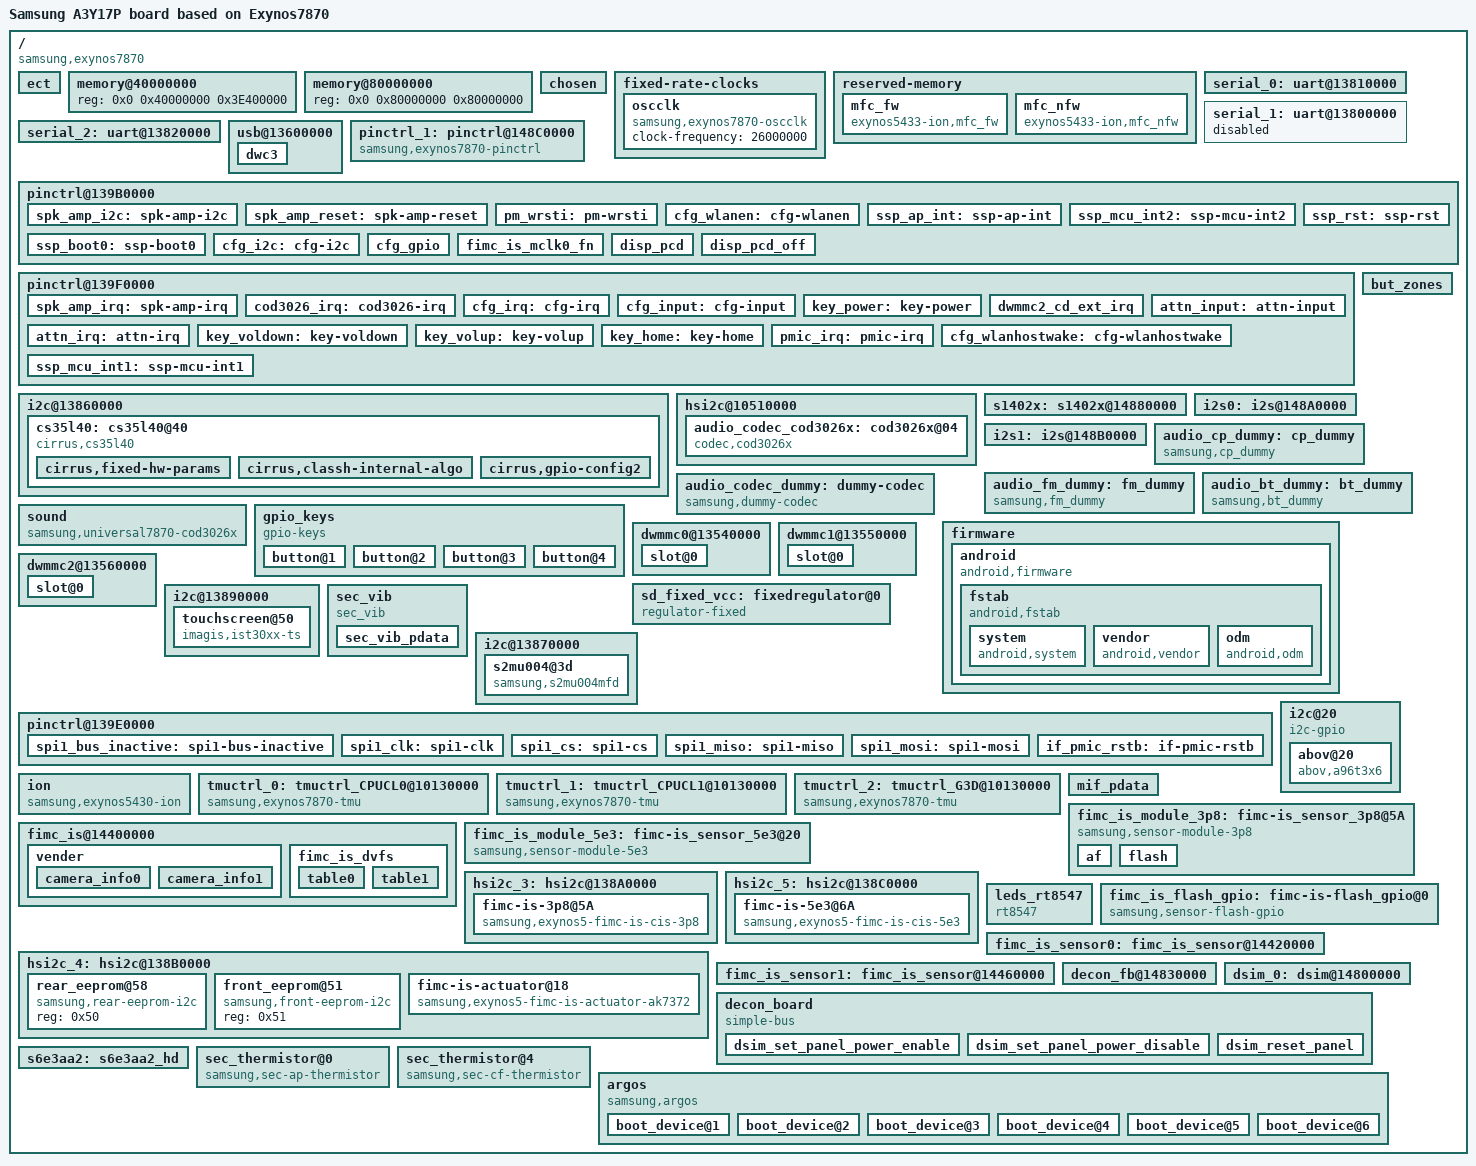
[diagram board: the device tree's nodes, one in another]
/*
 * Copyright (c) 2016 Samsung Electronics Co., Ltd.
 *		http://www.samsung.com
 *
 * This program is free software; you can redistribute it and/or modify
 * it under the terms of the GNU General Public License version 2 as
 * published by the Free Software Foundation.
*/

#include "exynos7870-rmem-3000MB.dtsi"
#include "exynos7870.dtsi"

/ {
	model = "Samsung A3Y17P board based on Exynos7870";
	compatible = "samsung,exynos7870", "samsung,universal7870";

	ect {
		parameter_address = <0x90000000>;
		parameter_size = <0x14000>;	/* u-boot always overwrites this value. */
	};

	memory@40000000 {
		device_type = "memory";
		reg = <0x0 0x40000000 0x3E400000>;
	};

	memory@80000000 {
		device_type = "memory";
		reg = <0x0 0x80000000 0x80000000>;
	};

	chosen {
		bootargs = "console=ram ess_setup=0x46000000 androidboot.hardware=samsungexynos7870 androidboot.selinux=disabled firmware_class.path=/vendor/firmware androidboot.debug_level=0x4948 reserve-fimc=0";
		linux,initrd-start = <0x42000000>;
		linux,initrd-end = <0x420FFFFF>;
	};

	fixed-rate-clocks {
		oscclk {
			compatible = "samsung,exynos7870-oscclk";
			clock-frequency = <26000000>;
		};
	};

	reserved-memory {
		#address-cells = <2>;
		#size-cells = <1>;
		ranges;

		mfc_fw {
			compatible = "exynos5433-ion,mfc_fw";
			secure;
			reg = <0x0 0xAE800000 0x200000>;
			id = <8>;
		};

		mfc_nfw {
			compatible = "exynos5433-ion,mfc_nfw";
			reg = <0x0 0xAE600000 0x200000>;
			id = <12>;
		};
	};

	serial_0: uart@13810000 {
		status = "okay";
	};

	serial_1: uart@13800000 {
		status = "disabled";
	};

	serial_2: uart@13820000 {
		status = "okay";
	};

	usb@13600000 {
		status = "okay";

		dwc3 {
			maximum-speed = "high-speed";
			dr_mode = "otg";
			is_not_vbus_pad;
		};
	};

	pinctrl_1: pinctrl@148C0000 {
		compatible = "samsung,exynos7870-pinctrl";
		reg = <0x0 0x148C0000 0x1000>;
		interrupts = <0 68 0>;
	};

	pinctrl@139B0000 {
		spk_amp_i2c: spk-amp-i2c {
			samsung,pins = "gpc9-1", "gpc9-0";
			samsung,pin-function = <2>;
			samsung,pin-pud = <0>;
		};

		spk_amp_reset: spk-amp-reset {
			samsung,pins = "gpd1-5";
			samsung,pin-function = <1>;
			samsung,pin-pud = <0>;
			samsung,pin-val = <0>;
			samsung,pin-con-pdn = <3>;
			samsung,pin-pud-pdn = <0>;
		};
	};

	pinctrl@139F0000 {
		spk_amp_irq: spk-amp-irq {
			samsung,pins = "gpa2-5";
			samsung,pin-function = <0xf>;
			samsung,pin-pud = <0>;
		};

		cod3026_irq: cod3026-irq {
			samsung,pins = "gpa0-4";
			samsung,pin-pud = <3>;
			samsung,pin-drv = <3>;
		};
	};

	i2c@13860000 {
		status = "okay";
		samsung,i2c-max-bus-freq = <400000>;
		pinctrl-names = "default";
		pinctrl-0 = <&spk_amp_i2c &spk_amp_reset &spk_amp_irq>;

		cs35l40: cs35l40@40 {
			#sound-dai-cells = <1>;
			compatible = "cirrus,cs35l40";
			reg = <0x40>;

			interrupt-parent = <&gpa2>;
			interrupts = <5 0 0>;

			cirrus,boost-peak-milliamp = <3100>;
			cirrus,temp-warn-threshold = <2>;

			cirrus,dsp-noise-gate-enable;
			cirrus,dsp-noise-gate-threshold = <0x3>;
			cirrus,dsp-noise-gate-delay = <0x7>;

			cirrus,hw-noise-gate-select = <0x3F>;
			cirrus,hw-noise-gate-delay = <0x7>;
			cirrus,hw-noise-gate-threshold = <0x7>;

			reset-gpios = <&gpd1 5 0>;

			cirrus,fixed-hw-params {
				cirrus,fixed-rate = <48000>;
				cirrus,fixed-width = <16>;
				cirrus,fixed-wl = <16>;
			};

			cirrus,classh-internal-algo {
				cirrus,classh-headroom = <0xb>;
				cirrus,classh-release-rate = <0x4>;
				cirrus,classh-mem-depth = <0x5>;
				cirrus,classh-wk-fet-delay = <0x4>;
				cirrus,classh-wk-fet-thld = <0x1>;
			};

			cirrus,gpio-config2 {
				cirrus,gpio-src-select = <0x4>;
				cirrus,gpio-output-enable;
			};
		};
	};

	but_zones: but_zones {
		#list-but-cells = <3>;
	};

	hsi2c@10510000 {
		audio_codec_cod3026x: cod3026x@04 {
			compatible = "codec,cod3026x";
			reg = <0x04>;
			ten-bit-address;
			vdd-supply = <&ldo25_reg>;
			pinctrl-names = "default";
			pinctrl-0 = <&cod3026_irq>;
			interrupt-parent = <&gpa0>;
			gpios = <&gpa0 4 0xf &gpd2 1 0x1>;
			ant-det-gpio = <&gpa2 3 0xf>;
			mic-bias1-voltage = <1>;
			mic-bias2-voltage = <1>;
			mic-bias-ldo-voltage = <3>;
			use-det-adc-mode;
			use-det-gdet-adc-mode = <2>;
			io-channels = <&exynos_adc 2>;
			io-channel-names = "adc-jack";
			#io-channel-cells = <1>;
			io-channel-ranges;
			but-zones-list = <&but_zones 226 0 390>, /* send/end */
					<&but_zones 582 391 465>, /* google */
					<&but_zones 115 466 650>, /* vol up */
					<&but_zones 114 651 1100>; /* vol down */
			mic-adc-range = <1430>;
			ant-adc-range = <3560>;
			mic-det-delay = <550>;
		};
	};

	s1402x: s1402x@14880000 {
		pinctrl-names = "default", "idle", "bt", "bt-idle", "fm", "fm-idle";
		pinctrl-0 = <&i2s_pmic_amp_bus
			&i2s_amp_bus>;
		pinctrl-1 = <&i2s_pmic_amp_bus_idle
			&i2s_amp_bus_idle> ;
		pinctrl-2 = <&i2s_bt_bus>;
		pinctrl-3 = <&i2s_bt_bus_idle>;
		pinctrl-4 = <&i2s_bt_bus>;
		pinctrl-5 = <&i2s_bt_bus_idle>;

		bt-fm-combo;
		status = "okay";
	};

	i2s0: i2s@148A0000 {
		status = "okay";
	};

	i2s1: i2s@148B0000 {
		status = "okay";
	};

	audio_cp_dummy: cp_dummy {
			compatible = "samsung,cp_dummy";
			status = "okay";
	};

	audio_fm_dummy: fm_dummy {
			compatible = "samsung,fm_dummy";
			status = "okay";
	};

	audio_bt_dummy: bt_dummy {
			compatible = "samsung,bt_dummy";
			status = "okay";
	};

	audio_codec_dummy: dummy-codec {
			compatible = "samsung,dummy-codec";
			status = "okay";
	};

	sound {
		compatible = "samsung,universal7870-cod3026x";
		samsung,audio-cpu = <&i2s0      /* primary */
			&i2s0                    /* secondary */
			&audio_cp_dummy
			&audio_bt_dummy
			&audio_fm_dummy
			&i2s1			/*AMP for AP */
			&audio_cp_dummy		/*AMP for CP */
			&eax
			&eax
			&eax
			&eax>;
		samsung,audio-codec = <&audio_codec_cod3026x
			&audio_codec_cod3026x
			&audio_codec_cod3026x
			&audio_codec_dummy
			&audio_codec_cod3026x
			&audio_codec_dummy
			&audio_codec_dummy
			&audio_codec_cod3026x
			&audio_codec_cod3026x
			&audio_codec_cod3026x
			&audio_codec_cod3026x>;
		samsung,audio-amp-num = <1>;
		samsung,audio-amp = <&cs35l40
			&cs35l40
			&cs35l40
			&audio_codec_dummy
			&cs35l40
			&cs35l40
			&audio_codec_dummy
			&cs35l40
			&cs35l40
			&cs35l40
			&cs35l40>;
		samsung,audio-amp-dai-name = "cs35l40-pcm",
			"cs35l40-pcm",
			"cs35l40-pcm",
			"dummy-aif2",
			"cs35l40-pcm",
			"cs35l40-pcm",
			"dummy-aif2",
			"cs35l40-pcm",
			"cs35l40-pcm",
			"cs35l40-pcm",
			"cs35l40-pcm";
		mic-bias-mode = <1 1 2 0>;
		samsung,auxdev = <&s1402x>;
		status = "okay";
	};

	gpio_keys {
		compatible = "gpio-keys";
		pinctrl-names = "default";
		pinctrl-0 = <&key_power &key_voldown &key_volup &key_home>;
		#address-cells = <1>;
		#size-cells = <0>;

		button@1 {
			label = "gpio-keys: KEY_POWER";
			interrupts = <0 0 0>;
			interrupt-parent = <&gpa0>;
			linux,code = <116>;
			gpios = <&gpa0 0 0xf>;
			gpio-key,wakeup = <1>;
		};
		button@2 {
			label = "gpio-keys: KEY_VOLUMEDOWN";
			interrupts = <1 0 0>;
			interrupt-parent = <&gpa2>;
			linux,code = <114>;
			gpios = <&gpa2 1 0xf>;
		};
		button@3 {
			label = "gpio-keys: KEY_VOLUMEUP";
			interrupts = <0 0 0>;
			interrupt-parent = <&gpa2>;
			linux,code = <115>;
			gpios = <&gpa2 0 0xf>;
		};
		button@4 {
			label = "gpio-keys: KEY_HOMEPAGE";
			interrupts = <7 0 0>;
			interrupt-parent = <&gpa1>;
			linux,code = <172>;
			gpios = <&gpa1 7 0xf>;
			gpio-key,wakeup = <1>;
		};
	};

	firmware {
		android {
			compatible = "android,firmware";
			fstab {
				compatible = "android,fstab";
				system {
					compatible = "android,system";
					dev = "/dev/block/platform/13540000.dwmmc0/by-name/SYSTEM";
					type = "ext4";
					mnt_flags = "ro";
					fsmgr_flags = "wait";
				};
				vendor {
					compatible = "android,vendor";
					dev = "/dev/block/platform/13540000.dwmmc0/by-name/VENDOR";
					type = "ext4";
					mnt_flags = "ro";
					fsmgr_flags = "wait";
				};
				odm {
					compatible = "android,odm";
					dev = "/dev/block/platform/13540000.dwmmc0/by-name/ODM";
					type = "ext4";
					mnt_flags = "ro";
					fsmgr_flags = "wait";
				};
			};
		};
	};

	dwmmc0@13540000 {
		status = "okay";
		num-slots = <1>;
		broken-cd;
		use-smu;
		fixed_voltage;
		clock-gate;
		supports-highspeed;
		mmc-ddr-1_8v;
		mmc-hs200-1_8v;
		mmc-hs400-1_8v;
		mmc-shutdown-poweroff;
		pm-skip-mmc-resume-init;
		supports-8bit;
		supports-cmd23;
		supports-erase;
		enable-ulp-mode;
		supports-hs400-enhanced-strobe;
		use-fine-tuning;
		bypass-for-allpass;
		card-init-hwacg-ctrl;
		fifo-depth = <0x40>;
		non-removable;
		desc-size = <4>;
		card-detect-delay = <200>;
		data-timeout = <200>;
		clock-frequency = <800000000>;
		samsung,dw-mshc-ciu-div = <3>;
		samsung,dw-mshc-txdt-crc-timer-fastlimit = <0x34>;
		samsung,dw-mshc-txdt-crc-timer-initval = <0x38>;
		samsung,dw-mshc-ddr200-delay-line = <0x60>;
		samsung,dw-mshc-sdr-timing = <3 0 4 0>;
		samsung,dw-mshc-ddr-timing = <3 0 4 2>;
		samsung,dw-mshc-hs200-timing = <3 0 3 0>;
		samsung,dw-mshc-ddr200-timing = <1 0 4 0>;
		samsung,dw-mshc-ddr200-ulp-timing = <3 0 3 0>;

		num-ref-clks = <12>;
		ciu_clkin = <25 50 50 25 50 100 200 50 50 200 200 200>;

		/* Swapping clock drive strength */
		clk-drive-number = <6>;
		pinctrl-names = "default",
			"fast-slew-rate-1x",
			"fast-slew-rate-2x",
			"fast-slew-rate-3x",
			"fast-slew-rate-4x",
			"fast-slew-rate-5x",
			"fast-slew-rate-6x";
		pinctrl-0 = <&sd0_clk &sd0_cmd &sd0_rdqs &sd0_bus1 &sd0_bus4 &sd0_bus8>;
		pinctrl-1 = <&sd0_clk_fast_slew_rate_1x>;
		pinctrl-2 = <&sd0_clk_fast_slew_rate_2x>;
		pinctrl-3 = <&sd0_clk_fast_slew_rate_3x>;
		pinctrl-4 = <&sd0_clk_fast_slew_rate_4x>;
		pinctrl-5 = <&sd0_clk_fast_slew_rate_5x>;
		pinctrl-6 = <&sd0_clk_fast_slew_rate_6x>;
		slot@0 {
			reg = <0>;
			bus-width = <8>;
		};
	};

	dwmmc1@13550000 {
		status = "okay";
		num-slots = <1>;
		channel = <1>;
		fixed_voltage;
		clock-gate;
		enable-cclk-on-suspend;
		caps-control;
		supports-highspeed;
		supports-4bit;
		sd-uhs-sdr104;
		keep-power-in-suspend;
		pm-ignore-notify;
		card-detect-type-external;
		use-broken-voltage;
		use-fine-tuning;
		ignore-phase = <(1 << 7)>;
		fifo-depth = <0x40>;
		card-detect-delay = <200>;
		samsung,dw-mshc-ciu-div = <3>;
		samsung,dw-mshc-sdr-timing = <3 0 3 0>;
		samsung,dw-mshc-ddr-timing = <3 0 2 1>;
		samsung,dw-mshc-sdr50-timing = <3 0 4 2>;
		samsung,dw-mshc-sdr104-timing = <3 0 3 0>;
		clk_pin = "gpr2-0";
		clk_addr = "13750000.pinctrl";
		clk_val = <0x2>;
		clk_str_num = <4>;
		num-ref-clks = <9>;
		ciu_clkin = <25 50 50 25 50 100 200 50 50>;

		pinctrl-names = "default";
		pinctrl-0 = <&sd1_clk &sd1_cmd &sd1_bus1 &sd1_bus4>;
		slot@0 {
			reg = <0>;
			bus-width = <4>;
		};
	};

	dwmmc2@13560000 {
		status = "okay";
		num-slots = <1>;
		supports-highspeed;
		supports-4bit;
		supports-cmd23;
		supports-erase;
		sd-uhs-sdr50;
		sd-uhs-sdr104;
		card-detect-gpio;
		clock-gate;
		bypass-smu;
		bypass-for-allpass;
		use-fine-tuning;
		card-init-hwacg-ctrl;
		only_once_tune;
		//skip-init-mmc-scan; /* temporary disable */
		samsung,voltage-int-extra = <0x7>;
		ignore-phase = <(1 << 7)>;
		fifo-depth = <0x40>;
		desc-size = <8>;
		card-detect-delay = <200>;
		data-timeout = <200>;
		hto-timeout = <550>;
		samsung,dw-mshc-ciu-div = <3>;
		clock-frequency = <800000000>;
		samsung,dw-mshc-sdr-timing = <3 0 3 0>;
		samsung,dw-mshc-ddr-timing = <3 0 2 1>;
		samsung,dw-mshc-sdr50-timing = <3 0 4 2>;
		samsung,dw-mshc-sdr104-timing = <3 0 3 0>;

		num-ref-clks = <9>;
		ciu_clkin = <25 50 50 25 50 100 200 50 50>;

		/* Swapping clock drive strength */
		clk-drive-number = <4>;
		pinctrl-names = "default",
			"fast-slew-rate-1x",
			"fast-slew-rate-2x",
			"fast-slew-rate-3x",
			"fast-slew-rate-4x";
		pinctrl-0 = <&sd2_clk &sd2_cmd &sd2_bus1 &sd2_bus4 &dwmmc2_cd_ext_irq>;
		pinctrl-1 = <&sd2_clk_fast_slew_rate_1x>;
		pinctrl-2 = <&sd2_clk_fast_slew_rate_2x>;
		pinctrl-3 = <&sd2_clk_fast_slew_rate_3x>;
		pinctrl-4 = <&sd2_clk_fast_slew_rate_4x>;

		card-detect = <&gpa0 1 0xf>;
		card-detect-gpio;
		sec-sd-slot-type = <2>; /* Hybrid SD slot */

		slot@0 {
			reg = <0>;
			bus-width = <4>;
			disable-wp;
		};
	};

	sd_fixed_vcc: fixedregulator@0 {
		compatible = "regulator-fixed";
		regulator-name = "vmmc";
		gpio = <&gpc0 0 1>;
		regulator-min-microvolt = <2800000>;
		regulator-max-microvolt = <2800000>;
		enable-active-high;
		regulator-initial-mode = <0>;
	};


	i2c@13890000 {
		samsung,i2c-sda-delay = <100>;
		samsung,i2c-max-bus-freq = <400000>;
		status = "okay";
		#address-cells = <1>;
		#size-cells = <0>;
		touchscreen@50 {
			compatible = "imagis,ist30xx-ts";
			reg = <0x50>;
			pinctrl-names = "on_state", "off_state";
			pinctrl-0 = <&attn_irq>;
			pinctrl-1 = <&attn_input>;
			imagis,irq-gpio = <&gpa0 6 0>;
			imagis,regulator_avdd = "tsp_avdd";
			imagis,fw-bin = <1>;
			imagis,octa-hw = <1>;
			imagis,ic-version = "ist3038h";
			imagis,project-name = "a3xpre";
//			imagis,pat_function = <1>;
		};
	};

	pinctrl@139F0000 {
		cfg_irq: cfg-irq {
			samsung,pins = "gpa1-4";
			samsung,pin-function = <0xf>;
			samsung,pin-pud = <3>;
			samsung,pin-drv = <0>;
		};
		cfg_input: cfg-input {
			samsung,pins = "gpa1-4";
			samsung,pin-function = <0>;
			samsung,pin-pud = <0>;
			samsung,pin-drv = <0>;
		};
	};

	sec_vib {
		compatible = "sec_vib";
		sec_vib_pdata {
			status = "okay";
			sec_vib,max_timeout = <10000>;
			sec_vib,ldo_type = <0>;		/* 0: pmic ldo, 1: external ldo */
			sec_vib,regulator = "VDD_MOTOR_3.3";
		};
	};

	i2c@13870000 {
		status = "okay";
		samsung,i2c-sda-delay = <100>;
		samsung,i2c-max-bus-freq = <400000>;

		s2mu004@3d {
			compatible = "samsung,s2mu004mfd";
			reg = <0x3d>;
			pinctrl-names = "default";
			pinctrl-0 = <&if_pmic_irq>;
			s2mu004,irq-gpio = <&gpa2 7 0>;
			s2mu004,wakeup;
		};
	};

	pinctrl@139F0000 {
		key_power: key-power {
			samsung,pins = "gpa0-0";
			samsung,pin-function = <0xf>;
			samsung,pin-pud = <0>;
			samsung,pin-drv = <0>;
		};
		dwmmc2_cd_ext_irq: dwmmc2_cd_ext_irq {
			samsung,pins = "gpa0-1";
			samsung,pin-function = <0xf>;
			samsung,pin-pud = <0>;
			samsung,pin-drv = <0>;
		};

		attn_input: attn-input {
			samsung,pins = "gpa0-6";
			samsung,pin-function = <0>;
			samsung,pin-pud = <0>;
			samsung,pin-drv = <0>;
		};
		attn_irq: attn-irq {
			samsung,pins = "gpa0-6";
			samsung,pin-function = <0xf>;
			samsung,pin-pud = <0>;
			samsung,pin-drv = <0>;
		};

		key_voldown: key-voldown {
			samsung,pins = "gpa2-1";
			samsung,pin-function = <0xf>;
			samsung,pin-pud = <0>;
			samsung,pin-drv = <0>;
		};

		key_volup: key-volup {
			samsung,pins = "gpa2-0";
			samsung,pin-function = <0xf>;
			samsung,pin-pud = <0>;
			samsung,pin-drv = <0>;
		};

		key_home: key-home {
			samsung,pins = "gpa1-7";
			samsung,pin-function = <0xf>;
			samsung,pin-pud = <0>;
			samsung,pin-drv = <0>;
		};
		pmic_irq: pmic-irq {
			samsung,pins = "gpa0-2";
			samsung,pin-pud = <3>;
			samsung,pin-drv = <3>;
		};

		cfg_wlanhostwake: cfg-wlanhostwake {
			samsung,pins = "gpa2-2";
			samsung,pin-function = <1>;
			samsung,pin-pud = <3>;
		};
		ssp_mcu_int1: ssp-mcu-int1 {
			samsung,pins = "gpa0-7";
			samsung,pin-function = <0>;
			samsung,pin-pud = <0>;
			samsung,pin-drv = <0>;
		};

	};

	pinctrl@139E0000 {
		/* SPI_FP */
		spi1_bus_inactive: spi1-bus-inactive {
			samsung,pins = "gpc7-3", "gpc7-2", "gpc7-1", "gpc7-0";
			samsung,pin-function = <0>;
			samsung,pin-pud = <1>;
			samsung,pin-drv = <2>;
		};
		spi1_clk: spi1-clk {
			samsung,pins = "gpc7-0";
			samsung,pin-function = <2>;
			samsung,pin-pud = <1>;
			samsung,pin-drv = <2>;
		};
		spi1_cs: spi1-cs {
			samsung,pins = "gpc7-1";
			samsung,pin-function = <2>;
			samsung,pin-pud = <3>;
			samsung,pin-drv = <2>;
		};
		spi1_miso: spi1-miso {
			samsung,pins = "gpc7-2";
			samsung,pin-function = <2>;
			samsung,pin-pud = <0>;
			samsung,pin-drv = <2>;
		};
		spi1_mosi: spi1-mosi {
			samsung,pins = "gpc7-3";
			samsung,pin-function = <2>;
			samsung,pin-pud = <1>;
			samsung,pin-drv = <2>;
		};
	};

	pinctrl@139E0000 {
		if_pmic_rstb: if-pmic-rstb {
			samsung,pins = "gpc7-4";
			samsung,pin-function = <2>;
			samsung,pin-pud = <3>;
			samsung,pin-con-pdn = <3>;
		};
	};

	pinctrl@139B0000 {
		/* Warm reset information from AP */
		pm_wrsti: pm-wrsti {
			samsung,pins = "gpd1-0";
			samsung,pin-con-pdn = <3>;
		};
	};

	pinctrl@139B0000 {
		cfg_wlanen: cfg-wlanen  {       /* WLAN_EN */
			samsung,pins = "gpd3-6";
			samsung,pin-function = <1>;
			samsung,pin-pud = <0>;
			samsung,pin-drv = <3>;
			samsung,pin-con-pdn = <3>;
			samsung,pin-pud-pdn = <0>;
			samsung,pin-val = <0>;
		};
		ssp_ap_int: ssp-ap-int {
			samsung,pins = "gpd4-2";
			samsung,pin-function = <1>;
			samsung,pin-pud = <3>;
			samsung,pin-drv = <3>;
		};
		ssp_mcu_int2: ssp-mcu-int2{
			samsung,pins = "gpd3-7";
			samsung,pin-function = <0>;
			samsung,pin-pud = <0>;
			samsung,pin-drv = <0>;
		};
		ssp_boot0: ssp-boot0 {
			samsung,pins = "gpd4-3";
			samsung,pin-function = <1>;
			samsung,pin-pud = <1>;
			samsung,pin-drv = <3>;
		};
		ssp_rst: ssp-rst {
			samsung,pins = "gpd2-3";
			samsung,pin-function = <1>;
			samsung,pin-pud = <0>;
			samsung,pin-drv = <3>;
			samsung,pin-pud-pdn = <0>;
		};
	};

	pinctrl@139B0000 {
		cfg_i2c: cfg-i2c {
			samsung,pins = "gpc8-0", "gpc8-1";
			samsung,pin-function = <3>;
			samsung,pin-pud = <0>;
			samsung,pin-drv = <0>;
		};
		cfg_gpio: cfg_gpio {
			samsung,pins = "gpc8-0", "gpc8-1";
			samsung,pin-function = <0>;
			samsung,pin-pud = <0>;
			samsung,pin-drv = <0>;
		};
	};

	i2c@20{
		compatible = "i2c-gpio";
		gpios = <&gpc8 0 0 /* sda */
				&gpc8 1 0 /* scl */
				>;
		i2c-gpio,delay-us = <2>;
		#address-cells = <1>;
		#size-cells = <0>;
		status = "okay";
		pinctrl-names = "default","on_i2c","off_i2c";
		pinctrl-0 = <&cfg_i2c>;
		pinctrl-1 = <&cfg_i2c>;
		pinctrl-2 = <&cfg_gpio>;
		abov@20 {
			status = "okay";
			compatible = "abov,a96t3x6";
			pinctrl-names = "on_irq", "off_irq";
			pinctrl-0 = <&cfg_irq>;
			pinctrl-1 = <&cfg_input>;
			reg = <0x20>;
			interrupt-parent = <&gpa0>;
			abov,sda-gpio = <&gpc8 0 0>;
			abov,scl-gpio = <&gpc8 1 0>;
			abov,irq-gpio = <&gpa1 4 0>;
			abov,tkey_en-gpio = <&gpd1 6 0>;
			abov,firmware_name = "abov/a96t326_next_a3p.fw";
			abov,firmup_cmd = <0x32>;
			abov,bringup = <0>;
//			abov,light_version = <170309 3>;	/* light_version light_table_num */
//			abov,octa_id = <1 2 8>;	/* black, white, pink */
//			abov,light_reg = <0x05 0x05 0x0F>;
		};
	};

	ion {
		compatible = "samsung,exynos5430-ion";
	};

	tmuctrl_0: tmuctrl_CPUCL0@10130000 {
		compatible = "samsung,exynos7870-tmu";
		reg = <0x0 0x10130000 0x200>;
		interrupts = <0 435 0>;
		max_trigger_level = <8>;
		non_hw_trigger_levels = <7>;

		/* Throttling Level */
		trigger_levels_0 = <76>;
		trigger_levels_1 = <81>;
		trigger_levels_2 = <86>;
		trigger_levels_3 = <91>;
		trigger_levels_4 = <96>;
		trigger_levels_5 = <101>;
		trigger_levels_6 = <111>;
		trigger_levels_7 = <115>;

		trigger_enable_0 = <ENABLE>;
		trigger_enable_1 = <ENABLE>;
		trigger_enable_2 = <ENABLE>;
		trigger_enable_3 = <ENABLE>;
		trigger_enable_4 = <ENABLE>;
		trigger_enable_5 = <ENABLE>;
		trigger_enable_6 = <ENABLE>;
		trigger_enable_7 = <ENABLE>;

		trigger_type_0 = <THROTTLE_ACTIVE>;
		trigger_type_1 = <THROTTLE_ACTIVE>;
		trigger_type_2 = <THROTTLE_ACTIVE>;
		trigger_type_3 = <THROTTLE_ACTIVE>;
		trigger_type_4 = <THROTTLE_ACTIVE>;
		trigger_type_5 = <THROTTLE_ACTIVE>;
		trigger_type_6 = <THROTTLE_ACTIVE>;
		trigger_type_7 = <HW_TRIP>;

		freq_tab_count = <5>;

		freq_clip_max_0 = <1586000>;
		freq_clip_max_1 = <1248000>;
		freq_clip_max_2 = <1248000>;
		freq_clip_max_3 = <546000>;
		freq_clip_max_4 = <546000>;

		cooling_level_0 = <76>;
		cooling_level_1 = <81>;
		cooling_level_2 = <86>;
		cooling_level_3 = <91>;
		cooling_level_4 = <96>;
	};

	tmuctrl_1: tmuctrl_CPUCL1@10130000 {
		compatible = "samsung,exynos7870-tmu";
		reg = <0x0 0x10130000 0x200>;
		interrupts = <0 435 0>;
		max_trigger_level = <8>;
		non_hw_trigger_levels = <7>;

		/* Throttling Level */
		trigger_levels_0 = <76>;
		trigger_levels_1 = <81>;
		trigger_levels_2 = <86>;
		trigger_levels_3 = <91>;
		trigger_levels_4 = <96>;
		trigger_levels_5 = <101>;
		trigger_levels_6 = <111>;
		trigger_levels_7 = <115>;

		trigger_enable_0 = <ENABLE>;
		trigger_enable_1 = <ENABLE>;
		trigger_enable_2 = <ENABLE>;
		trigger_enable_3 = <ENABLE>;
		trigger_enable_4 = <ENABLE>;
		trigger_enable_5 = <ENABLE>;
		trigger_enable_6 = <ENABLE>;
		trigger_enable_7 = <ENABLE>;

		trigger_type_0 = <THROTTLE_ACTIVE>;
		trigger_type_1 = <THROTTLE_ACTIVE>;
		trigger_type_2 = <THROTTLE_ACTIVE>;
		trigger_type_3 = <THROTTLE_ACTIVE>;
		trigger_type_4 = <THROTTLE_ACTIVE>;
		trigger_type_5 = <THROTTLE_ACTIVE>;
		trigger_type_6 = <THROTTLE_ACTIVE>;
		trigger_type_7 = <HW_TRIP>;

		freq_tab_count = <5>;

		freq_clip_max_0 = <1586000>;
		freq_clip_max_1 = <1248000>;
		freq_clip_max_2 = <1248000>;
		freq_clip_max_3 = <546000>;
		freq_clip_max_4 = <546000>;

		cooling_level_0 = <76>;
		cooling_level_1 = <81>;
		cooling_level_2 = <86>;
		cooling_level_3 = <91>;
		cooling_level_4 = <96>;

		hotplug_enable = <1>;
		hotplug_in_threshold = <91>;
		hotplug_out_threshold = <96>;
	};

	tmuctrl_2: tmuctrl_G3D@10130000 {
		compatible = "samsung,exynos7870-tmu";
		reg = <0x0 0x10130000 0x200>;
		interrupts = <0 435 0>;
		max_trigger_level = <8>;
		non_hw_trigger_levels = <7>;

		/* Throttling Level */
		trigger_levels_0 = <76>;
		trigger_levels_1 = <81>;
		trigger_levels_2 = <86>;
		trigger_levels_3 = <91>;
		trigger_levels_4 = <96>;
		trigger_levels_5 = <101>;
		trigger_levels_6 = <111>;
		trigger_levels_7 = <115>;

		trigger_enable_0 = <ENABLE>;
		trigger_enable_1 = <ENABLE>;
		trigger_enable_2 = <ENABLE>;
		trigger_enable_3 = <ENABLE>;
		trigger_enable_4 = <ENABLE>;
		trigger_enable_5 = <ENABLE>;
		trigger_enable_6 = <ENABLE>;
		trigger_enable_7 = <ENABLE>;

		trigger_type_0 = <THROTTLE_ACTIVE>;
		trigger_type_1 = <THROTTLE_ACTIVE>;
		trigger_type_2 = <THROTTLE_ACTIVE>;
		trigger_type_3 = <THROTTLE_ACTIVE>;
		trigger_type_4 = <THROTTLE_ACTIVE>;
		trigger_type_5 = <THROTTLE_ACTIVE>;
		trigger_type_6 = <THROTTLE_ACTIVE>;
		trigger_type_7 = <HW_TRIP>;

		freq_tab_count = <6>;

		freq_clip_max_0 = <1246000>;
		freq_clip_max_1 = <1146000>;
		freq_clip_max_2 = <1001000>;
		freq_clip_max_3 = <728000>;
		freq_clip_max_4 = <343000>;
		freq_clip_max_5 = <343000>;

		cooling_level_0 = <76>;
		cooling_level_1 = <81>;
		cooling_level_2 = <86>;
		cooling_level_3 = <91>;
		cooling_level_4 = <96>;
		cooling_level_5 = <101>;

		/* gpu cooling related table */
		gpu_idx_num = <6>;
		/* flags, driver_data(index), frequency */
		gpu_cooling_table = < 0 0 1001000
				      0 1 845000
				      0 2 728000
				      0 3 545000
				      0 4 343000
				      0 5 TABLE_END>;
	};

	/* modem_interface */
	mif_pdata {
		reg = <0 0x10000 0x14>;
		pinctrl-names = "default";

		mif,ap_clk_table = <
			/* khz */
			1586000
			1482000
			1352000
			1248000
			1144000
			1014000
			902000
			839000
			757000
			676000
			546000
			449000
			345000
			>;

		mif,mif_clk_table = <
			/* khz */
			902000
			825000
			728000
			676000
			546000
			451000
			275000
			>;

		mif,int_clk_table = <
			/* khz */
			400000
			334000
			200000
			134000
			>;
	};

	fimc_is@14400000 {
		vender {
			rear_sensor_id = <30>; /* SENSOR_NAME_S5K3P8 */
			front_sensor_id = <17>; /* SENSOR_NAME_S5K5E3 */
			use_module_check;

			total_camera_num = <2>;
			camera_info0 {				// 0 : rear
				isp = <0>;				/* 0 : INT , 1 : EXT , 2 : SOC */
				cal_memory = <2>;		/* 0 : N , 1 : FROM , 2 : EEPROM , 3 : OTP  */
				read_version = <0>;		/* 0 : SYSFS , 1 : CAMON */

				core_voltage = <0>;		/* 0 : N , 1 : Y  */
				upgrade = <0>;			/* 0 : N , 1 : SYSFS , 2 : CAMON */
				companion = <0>;		/* 0 : N , 1 : Y  */
				ois = <0>;				/* 0 : N , 1 : Y  */
			};
			camera_info1 {				// 1 : front
				isp = <0>;				/* 0 : INT , 1 : EXT , 2 : SOC */
				cal_memory = <2>;		/* 0 : N , 1 : FROM , 2 : EEPROM , 3 : OTP  */
				read_version = <0>;		/* 0 : SYSFS , 1 : CAMON */

				core_voltage = <0>;		/* 0 : N , 1 : Y  */
				upgrade = <0>;			/* 0 : N , 1 : SYSFS , 2 : CAMON */
				companion = <0>;		/* 0 : N , 1 : Y  */
				ois = <0>;				/* 0 : N , 1 : Y  */
			};
		};

		fimc_is_dvfs {
			#define DVFS_INT_L0 400000
			#define DVFS_INT_L1 334000
			#define DVFS_INT_L2 200000
			#define DVFS_INT_L3 134000

			#define DVFS_CAM_L0 533000
			#define DVFS_CAM_L1 334000
			#define DVFS_CAM_L2 167000

			#define DVFS_MIF_L0 902000
			#define DVFS_MIF_L1 836000
			#define DVFS_MIF_L2 728000
			#define DVFS_MIF_L3 676000
			#define DVFS_MIF_L4 546000
			#define DVFS_MIF_L5 451000
			#define DVFS_MIF_L6 275000

			table0 {
				desc = "default Max version";

				default_int = <0>;
				default_cam = <DVFS_CAM_L0>;
				default_mif = <DVFS_MIF_L0>;
				default_i2c = <0>;

				front_preview_int = <0>;
				front_preview_cam = <DVFS_CAM_L1>;
				front_preview_mif = <DVFS_MIF_L0>;
				front_preview_i2c = <0>;

				front_capture_int = <0>;
				front_capture_cam = <DVFS_CAM_L1>;
				front_capture_mif = <DVFS_MIF_L0>;
				front_capture_i2c = <0>;

				front_video_int = <0>;
				front_video_cam = <DVFS_CAM_L1>;
				front_video_mif = <DVFS_MIF_L0>;
				front_video_i2c = <0>;

				front_video_whd_int = <0>;
				front_video_whd_cam = <DVFS_CAM_L1>;
				front_video_whd_mif = <DVFS_MIF_L0>;
				front_video_whd_i2c = <0>;

				front_video_capture_int = <0>;
				front_video_capture_cam = <DVFS_CAM_L1>;
				front_video_capture_mif = <DVFS_MIF_L0>;
				front_video_capture_i2c = <0>;

				front_video_whd_capture_int = <0>;
				front_video_whd_capture_cam = <DVFS_CAM_L1>;
				front_video_whd_capture_mif = <DVFS_MIF_L0>;
				front_video_whd_capture_i2c = <0>;

				front_vt1_int = <0>;
				front_vt1_cam = <DVFS_CAM_L1>;
				front_vt1_mif = <DVFS_MIF_L0>;
				front_vt1_i2c = <0>;

				front_vt2_int = <0>;
				front_vt2_cam = <DVFS_CAM_L1>;
				front_vt2_mif = <DVFS_MIF_L0>;
				front_vt2_i2c = <0>;

				front_companion_preview_int = <0>;
				front_companion_preview_cam = <DVFS_CAM_L1>;
				front_companion_preview_mif = <DVFS_MIF_L0>;
				front_companion_preview_i2c = <0>;

				front_companion_capture_int = <0>;
				front_companion_capture_cam = <DVFS_CAM_L1>;
				front_companion_capture_mif = <DVFS_MIF_L0>;
				front_companion_capture_i2c = <0>;

				front_companion_video_int = <0>;
				front_companion_video_cam = <DVFS_CAM_L1>;
				front_companion_video_mif = <DVFS_MIF_L0>;
				front_companion_video_i2c = <0>;

				front_companion_video_whd_int = <0>;
				front_companion_video_whd_cam = <DVFS_CAM_L1>;
				front_companion_video_whd_mif = <DVFS_MIF_L0>;
				front_companion_video_whd_i2c = <0>;

				front_companion_video_capture_int = <0>;
				front_companion_video_capture_cam = <DVFS_CAM_L1>;
				front_companion_video_capture_mif = <DVFS_MIF_L0>;
				front_companion_video_capture_i2c = <0>;

				front_companion_video_whd_capture_int = <0>;
				front_companion_video_whd_capture_cam = <DVFS_CAM_L1>;
				front_companion_video_whd_capture_mif = <DVFS_MIF_L0>;
				front_companion_video_whd_capture_i2c = <0>;

				rear_preview_fhd_int = <0>;
				rear_preview_fhd_cam = <DVFS_CAM_L0>;
				rear_preview_fhd_mif = <DVFS_MIF_L0>;
				rear_preview_fhd_i2c = <0>;

				rear_preview_whd_int = <0>;
				rear_preview_whd_cam = <DVFS_CAM_L0>;
				rear_preview_whd_mif = <DVFS_MIF_L0>;
				rear_preview_whd_i2c = <0>;

				rear_preview_uhd_int = <0>;
				rear_preview_uhd_cam = <DVFS_CAM_L0>;
				rear_preview_uhd_mif = <DVFS_MIF_L0>;
				rear_preview_uhd_i2c = <0>;

				rear_capture_int = <0>;
				rear_capture_cam = <DVFS_CAM_L0>;
				rear_capture_mif = <DVFS_MIF_L0>;
				rear_capture_i2c = <0>;

				rear_video_fhd_int = <0>;
				rear_video_fhd_cam = <DVFS_CAM_L0>;
				rear_video_fhd_mif = <DVFS_MIF_L0>;
				rear_video_fhd_i2c = <0>;

				rear_video_whd_int = <0>;
				rear_video_whd_cam = <DVFS_CAM_L0>;
				rear_video_whd_mif = <DVFS_MIF_L0>;
				rear_video_whd_i2c = <0>;

				rear_video_uhd_int = <0>;
				rear_video_uhd_cam = <DVFS_CAM_L0>;
				rear_video_uhd_mif = <DVFS_MIF_L0>;
				rear_video_uhd_i2c = <0>;

				rear_video_fhd_capture_int = <0>;
				rear_video_fhd_capture_cam = <DVFS_CAM_L0>;
				rear_video_fhd_capture_mif = <DVFS_MIF_L0>;
				rear_video_fhd_capture_i2c = <0>;

				rear_video_whd_capture_int = <0>;
				rear_video_whd_capture_cam = <DVFS_CAM_L0>;
				rear_video_whd_capture_mif = <DVFS_MIF_L0>;
				rear_video_whd_capture_i2c = <0>;

				rear_video_uhd_capture_int = <0>;
				rear_video_uhd_capture_cam = <DVFS_CAM_L0>;
				rear_video_uhd_capture_mif = <DVFS_MIF_L0>;
				rear_video_uhd_capture_i2c = <0>;

				dual_preview_int = <0>;
				dual_preview_cam = <DVFS_CAM_L0>;
				dual_preview_mif = <DVFS_MIF_L0>;
				dual_preview_i2c = <0>;

				dual_capture_int = <0>;
				dual_capture_cam = <DVFS_CAM_L0>;
				dual_capture_mif = <DVFS_MIF_L0>;
				dual_capture_i2c = <0>;

				dual_video_int = <0>;
				dual_video_cam = <DVFS_CAM_L0>;
				dual_video_mif = <DVFS_MIF_L0>;
				dual_video_i2c = <0>;

				dual_video_capture_int = <0>;
				dual_video_capture_cam = <DVFS_CAM_L0>;
				dual_video_capture_mif = <DVFS_MIF_L0>;
				dual_video_capture_i2c = <0>;

				preview_high_speed_fps_int = <0>;
				preview_high_speed_fps_cam = <DVFS_CAM_L0>;
				preview_high_speed_fps_mif = <DVFS_MIF_L0>;
				preview_high_speed_fps_i2c = <0>;

				video_high_speed_60fps_int = <0>;
				video_high_speed_60fps_cam = <DVFS_CAM_L0>;
				video_high_speed_60fps_mif = <DVFS_MIF_L0>;
				video_high_speed_60fps_i2c = <0>;

				video_high_speed_120fps_int = <0>;
				video_high_speed_120fps_cam = <DVFS_CAM_L0>;
				video_high_speed_120fps_mif = <DVFS_MIF_L0>;
				video_high_speed_120fps_i2c = <0>;

				video_high_speed_240fps_int = <0>;
				video_high_speed_240fps_cam = <DVFS_CAM_L0>;
				video_high_speed_240fps_mif = <DVFS_MIF_L0>;
				video_high_speed_240fps_i2c = <0>;

				max_int = <DVFS_INT_L0>;
				max_cam = <DVFS_CAM_L0>;
				max_mif = <DVFS_MIF_L0>;
				max_i2c = <0>;
			};

			table1 {
				desc = "HAL3 version";

				default_int = <0>;
				default_cam = <DVFS_CAM_L0>;
				default_mif = <DVFS_MIF_L0>;
				default_i2c = <0>;

				front_preview_int = <DVFS_INT_L1>;
				front_preview_cam = <DVFS_CAM_L1>;
				front_preview_mif = <DVFS_MIF_L0>;
				front_preview_i2c = <0>;

				front_capture_int = <0>;
				front_capture_cam = <DVFS_CAM_L1>;
				front_capture_mif = <DVFS_MIF_L0>;
				front_capture_i2c = <0>;

				front_video_int = <0>;
				front_video_cam = <DVFS_CAM_L1>;
				front_video_mif = <DVFS_MIF_L0>;
				front_video_i2c = <0>;

				front_video_whd_int = <0>;
				front_video_whd_cam = <DVFS_CAM_L1>;
				front_video_whd_mif = <DVFS_MIF_L0>;
				front_video_whd_i2c = <0>;

				front_video_capture_int = <0>;
				front_video_capture_cam = <DVFS_CAM_L1>;
				front_video_capture_mif = <DVFS_MIF_L0>;
				front_video_capture_i2c = <0>;

				front_video_whd_capture_int = <0>;
				front_video_whd_capture_cam = <DVFS_CAM_L1>;
				front_video_whd_capture_mif = <DVFS_MIF_L0>;
				front_video_whd_capture_i2c = <0>;

				front_vt1_int = <0>;
				front_vt1_cam = <DVFS_CAM_L1>;
				front_vt1_mif = <DVFS_MIF_L0>;
				front_vt1_i2c = <0>;

				front_vt2_int = <0>;
				front_vt2_cam = <DVFS_CAM_L1>;
				front_vt2_mif = <DVFS_MIF_L0>;
				front_vt2_i2c = <0>;

				front_companion_preview_int = <0>;
				front_companion_preview_cam = <DVFS_CAM_L1>;
				front_companion_preview_mif = <DVFS_MIF_L0>;
				front_companion_preview_i2c = <0>;

				front_companion_capture_int = <0>;
				front_companion_capture_cam = <DVFS_CAM_L1>;
				front_companion_capture_mif = <DVFS_MIF_L0>;
				front_companion_capture_i2c = <0>;

				front_companion_video_int = <0>;
				front_companion_video_cam = <DVFS_CAM_L1>;
				front_companion_video_mif = <DVFS_MIF_L0>;
				front_companion_video_i2c = <0>;

				front_companion_video_whd_int = <0>;
				front_companion_video_whd_cam = <DVFS_CAM_L1>;
				front_companion_video_whd_mif = <DVFS_MIF_L0>;
				front_companion_video_whd_i2c = <0>;

				front_companion_video_capture_int = <0>;
				front_companion_video_capture_cam = <DVFS_CAM_L1>;
				front_companion_video_capture_mif = <DVFS_MIF_L0>;
				front_companion_video_capture_i2c = <0>;

				front_companion_video_whd_capture_int = <0>;
				front_companion_video_whd_capture_cam = <DVFS_CAM_L1>;
				front_companion_video_whd_capture_mif = <DVFS_MIF_L0>;
				front_companion_video_whd_capture_i2c = <0>;

				rear_preview_fhd_int = <DVFS_INT_L1>;
				rear_preview_fhd_cam = <DVFS_CAM_L0>;
				rear_preview_fhd_mif = <DVFS_MIF_L0>;
				rear_preview_fhd_i2c = <0>;

				rear_preview_whd_int = <0>;
				rear_preview_whd_cam = <DVFS_CAM_L0>;
				rear_preview_whd_mif = <DVFS_MIF_L0>;
				rear_preview_whd_i2c = <0>;

				rear_preview_uhd_int = <0>;
				rear_preview_uhd_cam = <DVFS_CAM_L0>;
				rear_preview_uhd_mif = <DVFS_MIF_L0>;
				rear_preview_uhd_i2c = <0>;

				rear_capture_int = <0>;
				rear_capture_cam = <DVFS_CAM_L0>;
				rear_capture_mif = <DVFS_MIF_L0>;
				rear_capture_i2c = <0>;

				rear_video_fhd_int = <0>;
				rear_video_fhd_cam = <DVFS_CAM_L0>;
				rear_video_fhd_mif = <DVFS_MIF_L0>;
				rear_video_fhd_i2c = <0>;

				rear_video_whd_int = <0>;
				rear_video_whd_cam = <DVFS_CAM_L0>;
				rear_video_whd_mif = <DVFS_MIF_L0>;
				rear_video_whd_i2c = <0>;

				rear_video_uhd_int = <0>;
				rear_video_uhd_cam = <DVFS_CAM_L0>;
				rear_video_uhd_mif = <DVFS_MIF_L0>;
				rear_video_uhd_i2c = <0>;

				rear_video_fhd_capture_int = <0>;
				rear_video_fhd_capture_cam = <DVFS_CAM_L0>;
				rear_video_fhd_capture_mif = <DVFS_MIF_L0>;
				rear_video_fhd_capture_i2c = <0>;

				rear_video_whd_capture_int = <0>;
				rear_video_whd_capture_cam = <DVFS_CAM_L0>;
				rear_video_whd_capture_mif = <DVFS_MIF_L0>;
				rear_video_whd_capture_i2c = <0>;

				rear_video_uhd_capture_int = <0>;
				rear_video_uhd_capture_cam = <DVFS_CAM_L0>;
				rear_video_uhd_capture_mif = <DVFS_MIF_L0>;
				rear_video_uhd_capture_i2c = <0>;

				dual_preview_int = <0>;
				dual_preview_cam = <DVFS_CAM_L0>;
				dual_preview_mif = <DVFS_MIF_L0>;
				dual_preview_i2c = <0>;

				dual_capture_int = <0>;
				dual_capture_cam = <DVFS_CAM_L0>;
				dual_capture_mif = <DVFS_MIF_L0>;
				dual_capture_i2c = <0>;

				dual_video_int = <0>;
				dual_video_cam = <DVFS_CAM_L0>;
				dual_video_mif = <DVFS_MIF_L0>;
				dual_video_i2c = <0>;

				dual_video_capture_int = <0>;
				dual_video_capture_cam = <DVFS_CAM_L0>;
				dual_video_capture_mif = <DVFS_MIF_L0>;
				dual_video_capture_i2c = <0>;

				preview_high_speed_fps_int = <0>;
				preview_high_speed_fps_cam = <DVFS_CAM_L0>;
				preview_high_speed_fps_mif = <DVFS_MIF_L0>;
				preview_high_speed_fps_i2c = <0>;

				video_high_speed_60fps_int = <0>;
				video_high_speed_60fps_cam = <DVFS_CAM_L0>;
				video_high_speed_60fps_mif = <DVFS_MIF_L0>;
				video_high_speed_60fps_i2c = <0>;

				video_high_speed_120fps_int = <0>;
				video_high_speed_120fps_cam = <DVFS_CAM_L0>;
				video_high_speed_120fps_mif = <DVFS_MIF_L0>;
				video_high_speed_120fps_i2c = <0>;

				video_high_speed_240fps_int = <0>;
				video_high_speed_240fps_cam = <DVFS_CAM_L0>;
				video_high_speed_240fps_mif = <DVFS_MIF_L0>;
				video_high_speed_240fps_i2c = <0>;

				max_int = <DVFS_INT_L0>;
				max_cam = <DVFS_CAM_L0>;
				max_mif = <DVFS_MIF_L0>;
				max_i2c = <0>;
			};
		};
	};

	pinctrl@139B0000 {
		fimc_is_mclk0_fn: fimc_is_mclk0_fn {
			samsung,pins = "gpe0-0";
			samsung,pin-function = <2>;
			samsung,pin-pud = <0>;
			samsung,pin-drv = <1>;
		};
	};

	fimc_is_module_3p8: fimc-is_sensor_3p8@5A {
		compatible = "samsung,sensor-module-3p8";

		pinctrl-names = "pin0", "pin1";
		pinctrl-0 = <&fimc_is_mclk0_in &fimc_is_flash>;
		pinctrl-1 = <&fimc_is_mclk0_fn &fimc_is_flash>;

		position = <0>; /* Rear:0. Front:1 */
		id = <0>; /* sensor node id */
		mclk_ch = <0>;
		sensor_i2c_ch = <0>; /* I2C 0 */
		sensor_i2c_addr = <0x5A>;

		gpio_reset = <&gpf3 3 0x1>; /* sensor reset */
		gpio_cam_2p8_en = <&gpc2 3 0x1>; /* CAM_2P8 enable pin */
		gpio_camaf_2p8_en = <&gpd1 1 0x1>; /* CAM_AF_2P8 enable pin */
		gpio_cam_core_en = <&gpf4 1 0x1>; /* CAM_1P2 enable pin */
		status = "okay";

		af {
			product_name = <16>; /* ACTUATOR_NAME_AK7372 */
			i2c_addr = <0x18>;
			i2c_ch = <1>; /* I2C 0 */
		};

		flash {
			product_name = <11>; /* FLASH_GPIO */
			flash_first_gpio = <2>;
			flash_second_gpio = <1>;
		};
	};

	fimc_is_module_5e3: fimc-is_sensor_5e3@20 {
		compatible = "samsung,sensor-module-5e3";

		pinctrl-names = "pin0", "pin1";
		pinctrl-0 = <&fimc_is_mclk1_in>;
		pinctrl-1 = <&fimc_is_mclk1_fn>;

		position = <1>; /* Rear:0. Front:1 */
		id = <1>; /* sensor node id */
		mclk_ch = <1>;
		sensor_i2c_ch = <2>;
		sensor_i2c_addr = <0x20>;

		gpio_reset = <&gpf3 1 0x1>;
		gpio_vtcam_1p2_en = <&gpf4 2 0x1>; /* CAM_1P2 enable pin */
		gpio_sensor_a2p8_en = <&gpf3 2 0x1>; /* CAM_2P8 enable pin */
		status = "okay";
	};

	hsi2c_3: hsi2c@138A0000 {
		gpios = <&gpf0 0 0 &gpf0 1 0>;
		status = "okay";
		clock-frequency = <400000>;

		pinctrl-names = "default";
		pinctrl-0 = <&hs_i2c3_bus>;

		fimc-is-3p8@5A {
			compatible = "samsung,exynos5-fimc-is-cis-3p8";
			reg = <0x2D>;
			id = <0>; /* matching sensor id */
			fnum = <2>; /* F1_9: fimc-is-param.h */
			setfile = "setA";
		};
	};

	hsi2c_5: hsi2c@138C0000 {
		gpios = <&gpf0 2 0 &gpf0 3 0>;
		status = "okay";
		clock-frequency = <400000>;

		pinctrl-names = "default";
		pinctrl-0 = <&hs_i2c5_bus>;

		fimc-is-5e3@6A {
			compatible = "samsung,exynos5-fimc-is-cis-5e3";
			reg = <0x10>;
			id = <1>; /* matching sensor id */
			setfile = "setB";
		};
	};

	hsi2c_4: hsi2c@138B0000 {
		gpios = <&gpf1 0 0 &gpf1 1 0>;
		status = "okay";
		clock-frequency = <400000>;

		pinctrl-names = "default";
		pinctrl-0 = <&hs_i2c4_bus>;

		rear_eeprom@58 {
			compatible = "samsung,rear-eeprom-i2c";
			reg = <0x50>;
		};

		front_eeprom@51 {
			compatible = "samsung,front-eeprom-i2c";
			reg = <0x51>;
		};

		fimc-is-actuator@18 {
			compatible = "samsung,exynos5-fimc-is-actuator-ak7372";
			reg = <0x0C>;
			id = <0>; /* matching sensor id */
		};
	};

	leds_rt8547 {
		compatible = "rt8547";
		status = "okay";
		flash_control = <&gpd3 3 0x1>;
		flash_en = <&gpd3 2 0x1>;
		flash_current = <1200>; /* Max = 1600mA */
		movie_current = <100>; /* Max = 400mA */
		factory_current = <350>; /* Max = 400mA */
		pre_current = <150>; /* Max = 400mA */
	};

	fimc_is_flash_gpio: fimc-is-flash_gpio@0 {
		compatible = "samsung,sensor-flash-gpio";
		id = <0>; /* Rear  */
		status = "okay";

		flash-gpio = <&gpd3 2 0>;
		torch-gpio = <&gpd3 2 0>;
	};

	#define SENSOR_SCENARIO_NORMAL		0
	#define SENSOR_SCENARIO_VISION		1
	#define SENSOR_SCENARIO_EXTERNAL	2
	#define SENSOR_SCENARIO_OIS_FACTORY	3
	#define SENSOR_SCENARIO_VIRTUAL		9
	#define FLITE_ID_NOTHING 100

	fimc_is_sensor0: fimc_is_sensor@14420000 {
		scenario = <SENSOR_SCENARIO_NORMAL>;	/* Normal, Vision, OIS etc */
		id = <0>;
		csi_ch = <0>;
		flite_ch = <0>;
		is_bns = <1>;
		status = "okay";
	};

	fimc_is_sensor1: fimc_is_sensor@14460000 {
		scenario = <SENSOR_SCENARIO_NORMAL>;	/* Normal, Vision, OIS etc */
		id = <1>;
		csi_ch = <1>;
		flite_ch = <0>;
		is_bns = <1>;
		status = "okay";
	};

	decon_fb@14830000 {
		psr_mode = <2>;		/* 0: video mode, 1: DP command mode, 2: MIPI command mode */
		disp-pll-clk = <64000000>;
		disp-vclk = <64000000>;
		disp-eclk = <70000000>;
		disp-dvfs = <200000>;
		status = "okay";

		/* gpio_det = <&gpa2 5 0x1>; */
		gpio_pcd = <&gpd3 5 0x0>;
		/* gpio_err = <&gpd1 4 0x2>; */
	};

	dsim_0: dsim@14800000 {
		lcd_info = <&s6e3aa2>;
		decon_board = <&decon_board>;
		status = "okay";
	};

	pinctrl@139B0000 {
		disp_pcd: disp_pcd {
			samsung,pins = "gpd3-5";
			samsung,pin-function = <0xf>;
			samsung,pin-pud = <3>;
		};
		disp_pcd_off: disp_pcd_off {
			samsung,pins = "gpd3-5";
			samsung,pin-function = <0>;
			samsung,pin-pud = <1>;
		};
	};

	decon_board: decon_board {
		compatible = "simple-bus";
		pinctrl-names = "off", "on";
		pinctrl-0 = <&disp_pcd_off>;
		pinctrl-1 = <&disp_pcd>;

		gpio_lcd_rst = <&gpd3 4 0x1>;

		dsim_set_panel_power_enable {
			type =
			"regulator,enable",	"LCD_3P0",
			"regulator,enable",	"LCD_1P8",
			"delay,usleep",	"10000 11000";
		};
		dsim_set_panel_power_disable {
			type =
			"gpio,low",	"gpio_lcd_rst",
			"regulator,disable",	"LCD_1P8",
			"regulator,disable",	"LCD_3P0";
		};
		dsim_reset_panel {
			type =
			"delay,usleep",	"1000 1100",
			"gpio,high",	"gpio_lcd_rst",
			"delay,usleep",	"5000 6000",
			"gpio,low",	"gpio_lcd_rst",
			"delay,usleep",	"5000 6000",
			"gpio,high",	"gpio_lcd_rst",
			"delay,usleep",	"10000 11000";
		};
	};

	s6e3aa2: s6e3aa2_hd {
		mode = <2>;	/* 0: video mode, 1: DP command mode, 2: MIPI command mode */
		resolution = <720 1280>;
		size = <59 105>;
		ddi_type = <0>;
		timing,refresh = <60>;
		timing,h-porch = <1 1 1>;
		timing,v-porch = <10 3 1>;
		timing,dsi-hs-clk = <489>;
		timing,pms = <3 226 2>;
		timing,dsi-escape-clk = <16>;
	};

	sec_thermistor@0 {
		compatible = "samsung,sec-ap-thermistor";
		status = "okay";

		adc_array = <278 287 297 307 317 327 341 353 365 377
				389 404 418 432 446 460 474 490 506 522
				538 554 571 588 605 622 644 665 686 707
				728 759 789 819 849 879 911 943 975 1007
				1039 1068 1104 1136 1168 1200 1237 1274 1312 1350
				1388 1426 1466 1506 1546 1586 1630 1674 1718 1762
				1806 1846 1885 1924 1963 2002 2054 2104 2154 2204
				2254 2300 2345 2390 2435 2480 2514 2549 2584 2619
				2654 2703 2753 2803 2853 2903 2941 2978 3015 3052
				3089 3110 3130 3150 3170 3190 3229 3269 3309 3349
				3389 3407 3425 3443 3461 3480 3501 3524 3547 3570 3593>;
		temp_array = <900 890 880 870 860 850 840 830 820 810
					   800 790 780 770 760 750 740 730 720 710
					   700 690 680 670 660 650 640 630 620 610
					   600 590 580 570 560 550 540 530 520 510
					   500 490 480 470 460 450 440 430 420 410
					   400 390 380 370 360 350 340 330 320 310
					   300 290 280 270 260 250 240 230 220 210
					   200 190 180 170 160 150 140 130 120 110
					   100 90 80 70 60 50 40 30 20 10
					   0 (-10) (-20) (-30) (-40) (-50) (-60) (-70) (-80) (-90)
					   (-100) (-110) (-120) (-130) (-140) (-150) (-160) (-170) (-180) (-190) (-200)>;
		io-channels = <&exynos_adc 0>;
		io-channel-names = "adc-ap-temp";
		io-channel-ranges;
	};

	sec_thermistor@4 {
		compatible = "samsung,sec-cf-thermistor";
		status = "okay";

		adc_array = <243 298 353 426 499 604 708 830 964 1142
				1339 1527 1739 1943 2147 2375 2604 2809 3014 3172
				3331 3440 3548>;
		temp_array = <900 850 800 750 700 650 600 550 500 450
				400 350 300 250 200 150 100 50 0 (-50)
				(-100) (-150) (-200)>;
		io-channels = <&exynos_adc 4>;
		io-channel-names = "adc-cf-temp";
		io-channel-ranges;
	};

	argos {
		compatible = "samsung,argos";
		#address-cells = <1>;
		/*  The device number should be assigned for each device, e.g. "boot_device@1" and "boot_device@2".
		    Duplicated number is not allowed. Please refer the below example. */

		/* Table Format should be
		 * <Throughput(Mbps) ARM_min ARM_max KFC_min KFC_max MIF INT Task IRQ>
		 * ARM_min : Big Core's minimum frequency lock. 0 means not set,
		 * ARM_max : Big Core's maximum frequency lock. 0 means not set,
		 * KFC_min : Little Core's minimum frequency lock. 0 means not set,
		 * KFC_max : Little Core's maximum frequency lock. 0 means not set,
		 * MIF : MIF frequency lock. 0 means not set,
		 * INT : INT frequency lock. 0 means not set,
		 * Task : 1 - Set task affinity lock.
		 *        0 - Not set or unlock,
		 *              Task affinity should be predefined driver's code.
		 * IRQ : 1 - Set irq affinity lock.
		 *       0 - Not set or unlock,
		 *              Task affinity should be predefined driver's code.
		 */
		boot_device@1 {
			net_boost,label="IPC";
			net_boost,node="rmnet0 rmnet1 rmnet2 rmnet3 rmnet4 rmnet5 rmnet6 rmnet7 umts_dm0";
			net_boost,table_size = <4>;
			net_boost,table= <
				1 0 0 0 0 0 0 0 1
				20 0 0 839000 0 546000 100000 0 1
				50 0 0 1014000 0 836000 100000 0 1
				100 0 0 1482000 0 902000 100000 0 1
				>;
		};
		boot_device@2 {
			net_boost,label="P2P";
			net_boost,node="p2p-wlan0-0";
			net_boost,table_size = <3>;
			net_boost,table= <
				30 1014000 0 1014000 0 0 0 0 0
				50 1248000 0 1248000 0 0 0 0 0
				90 1352000 0 1352000 0 0 0 0 0
				>;
		};
		boot_device@3 {
			net_boost,label="WIFI TX";
			net_boost,node="wlan0";
			net_boost,table_size = <3>;
			net_boost,table= <
				20  902000  0  902000  0 0 0 0 0
				60  1014000 0  1014000 0 0 0 0 0
				120 1352000 0  1352000 0 0 0 0 0
				>;
		};
		boot_device@4 {
			net_boost,label="WIFI RX";
			net_boost,node="wlan0";
			net_boost,table_size = <1>;
			net_boost,table= <				
				100 1352000 0  1352000 0 0 0 0 0
				>;
		};
		boot_device@5 {
			net_boost,label="USB";
			net_boost,node="rndis0";
			net_boost,table_size = <1>;
			net_boost,table= <  1 0 0 0 0 0 0 0 1 >;
		};
		boot_device@6 {
			net_boost,label="CLAT";
			net_boost,node="clat clat4 v4-rmnet0 v4-rmnet1 v4-rmnet2 v4-rmnet3 v4-rmnet4 v4-rmnet5 v4-rmnet6 v4-rmnet7";
			net_boost,table_size = <3>;
			net_boost,table= <
				120 1352000 0 0 0 902000 0 0 0
				130 1482000 0 0 0 902000 0 0 0
				150 1586000 0 0 0 902000 0 0 0
				>;
		};

		/* Example
		   boot_device@2 {
		   net_boost,label="EMMC";
		   net_boost,node="";
		   net_boost,sysnode="/sys/class/mmc_host/mmc0/trans_count";
		   net_boost,table_size = <1>;
		   net_boost,table= <64 0 0 1300000 0 825000 400000 0 0>;
		   };
		   boot_device@3 {
		   net_boost,label="WIFI";
		   net_boost,node="wlan0";
		   net_boost,table_size = <3>;
		   net_boost,table= <60 1000000 0 800000 0 0 200000 0 0
		   100 1200000 0 1000000 0 0 200000 0 0
		   180 1700000 0 1100000 0 543000 267000 0 0>;
		   };
		   boot_device@4 {
		   net_boost,label="P2P";
		   net_boost,node="p2p-wlan0-0";
		   net_boost,table_size = <3>;
		   net_boost,table= <30 1000000 0 800000 0 0 200000 0 0
		   50 1200000 0 1000000 0 0 200000 0 0
		   90 1700000 0 1100000 0 543000 267000 0 0>;
		   };
		   boot_device@5 {
		   net_boost,label="CLAT";
		   net_boost,node="clat clat4";
		   net_boost,table_size = <3>;
		   net_boost,table= <120 1400000 0 0 0 825000 0 0 0
		   130 1500000 0 0 0 825000 0 0 0
		   150 1600000 0 0 0 825000 0 0 0>;
		   };
		 */
	};
};
